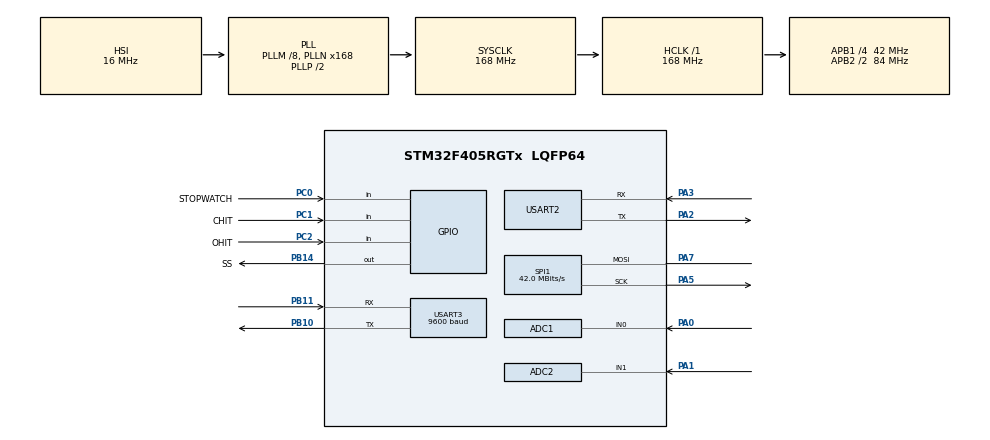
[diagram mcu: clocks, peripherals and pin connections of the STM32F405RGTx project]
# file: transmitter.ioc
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ADC1.Channel-0\#ChannelRegularConversion=ADC_CHANNEL_0
ADC1.NbrOfConversionFlag=1
ADC1.Rank-0\#ChannelRegularConversion=1
ADC1.SamplingTime-0\#ChannelRegularConversion=ADC_SAMPLETIME_28CYCLES
ADC1.master=1
ADC2.Channel-0\#ChannelRegularConversion=ADC_CHANNEL_1
ADC2.NbrOfConversionFlag=1
ADC2.Rank-0\#ChannelRegularConversion=1
ADC2.SamplingTime-0\#ChannelRegularConversion=ADC_SAMPLETIME_28CYCLES
Mcu.Family=STM32F4
Mcu.Name=STM32F405RGTx
Mcu.Package=LQFP64
NVIC.PriorityGroup=NVIC_PRIORITYGROUP_4
NVIC.TIM2_IRQn=true\:0\:0\:false\:false\:true\:true\:true\:true
PA0-WKUP.Signal=ADCx_IN0
PA1.Signal=ADCx_IN1
PA2.Mode=Asynchronous
PA2.Signal=USART2_TX
PA3.Mode=Asynchronous
PA3.Signal=USART2_RX
PA5.Mode=Simplex_Bidirectional_Master
PA5.Signal=SPI1_SCK
PA7.Mode=Simplex_Bidirectional_Master
PA7.Signal=SPI1_MOSI
PB10.Mode=Asynchronous
PB10.Signal=USART3_TX
PB11.Mode=Asynchronous
PB11.Signal=USART3_RX
PB14.GPIO_Label=SS
PB14.Signal=GPIO_Output
PC0.GPIO_Label=STOPWATCH
PC0.Signal=GPIO_Input
PC1.GPIO_Label=CHIT
PC1.Signal=GPIO_Input
PC2.GPIO_Label=OHIT
PC2.Signal=GPIO_Input
ProjectManager.HeapSize=0x200
ProjectManager.StackSize=0x400
ProjectManager.TargetToolchain=STM32CubeIDE
RCC.48MHZClocksFreq_Value=84000000
RCC.AHBFreq_Value=168000000
RCC.APB1CLKDivider=RCC_HCLK_DIV4
RCC.APB1Freq_Value=42000000
RCC.APB1TimFreq_Value=84000000
RCC.APB2CLKDivider=RCC_HCLK_DIV2
RCC.APB2Freq_Value=84000000
RCC.APB2TimFreq_Value=168000000
RCC.CortexFreq_Value=168000000
RCC.HCLKFreq_Value=168000000
RCC.HSE_VALUE=25000000
RCC.HSI_VALUE=16000000
RCC.LSE_VALUE=32768
RCC.PLLM=8
RCC.PLLN=168
RCC.SYSCLKFreq_VALUE=168000000
RCC.SYSCLKSource=RCC_SYSCLKSOURCE_PLLCLK
RCC.VCOOutputFreq_Value=336000000
SH.ADCx_IN0.0=ADC1_IN0,IN0
SH.ADCx_IN1.0=ADC2_IN1,IN1
SPI1.CalculateBaudRate=42.0 MBits/s
SPI1.Direction=SPI_DIRECTION_1LINE
SPI1.Mode=SPI_MODE_MASTER
SPI1.VirtualType=VM_MASTER
TIM2.Period=50000-1
TIM2.Prescaler=16800-1
USART2.VirtualMode=VM_ASYNC
USART3.BaudRate=9600
USART3.VirtualMode=VM_ASYNC
VP_TIM2_VS_ClockSourceINT.Mode=Internal
board=custom

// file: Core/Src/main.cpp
/* USER CODE BEGIN Header */
/**
  ******************************************************************************
  * @file           : main.c
  * @brief          : Main program body
  ******************************************************************************
  * @attention
  *
  * Copyright (c) 2025 STMicroelectronics.
  * All rights reserved.
  *
  * This software is licensed under terms that can be found in the LICENSE file
  * in the root directory of this software component.
  * If no LICENSE file comes with this software, it is provided AS-IS.
  *
  ******************************************************************************
  */
/* USER CODE END Header */
//#include "main.h"
extern "C" {
#include "main.h"  // good enough
}
#include "lora.hpp"

ADC_HandleTypeDef hadc1;
ADC_HandleTypeDef hadc2;

SPI_HandleTypeDef hspi1;

TIM_HandleTypeDef htim2;

UART_HandleTypeDef huart2;
UART_HandleTypeDef huart3;

void SystemClock_Config(void);
static void MX_GPIO_Init(void);
static void MX_ADC1_Init(void);
static void MX_ADC2_Init(void);
static void MX_TIM2_Init(void);
static void MX_USART2_UART_Init(void);
static void MX_USART3_UART_Init(void);
static void MX_SPI1_Init(void);

/* USER CODE BEGIN 0 */
void HAL_TIM_PeriodElapsedCallback(TIM_HandleTypeDef *htim)
  {
      if (htim->Instance == TIM2)
      {
    	  //ADC data to soc
    	  //lcd_update

          //HAL_GPIO_TogglePin(GPIOA, GPIO_PIN_5);  // Toggle the LED
      }
  }
/* USER CODE END 0 */

int main(void)
{

  /* MCU Configuration--------------------------------------------------------*/

  /* Reset of all peripherals, Initializes the Flash interface and the Systick. */
  HAL_Init();

  /* Configure the system clock */
  SystemClock_Config();

  /* Initialize all configured peripherals */
  MX_GPIO_Init();
  MX_ADC1_Init();
  MX_ADC2_Init();
  MX_TIM2_Init();
  MX_USART2_UART_Init();
  MX_USART3_UART_Init();
  MX_SPI1_Init();
  HAL_TIM_Base_Start_IT(&htim2);  // Start TIM2 in interrupt mode
  lora_init();

  /* Infinite loop */
  while (1)
  {
	  if(HAL_GPIO_ReadPin(GPIOC,CHIT_Pin)||HAL_GPIO_ReadPin(GPIOC, OHIT_Pin)||HAL_GPIO_ReadPin(GPIOC, STOPWATCH_Pin)){
		  if(HAL_GPIO_ReadPin(GPIOC,CHIT_Pin))
			  lora_send_char('2');
		  else if(HAL_GPIO_ReadPin(GPIOC, OHIT_Pin))
			  lora_send_char('1');
		  else if(HAL_GPIO_ReadPin(GPIOC, STOPWATCH_Pin)){
			  //do something
		  }
	  }
  }
}

void SystemClock_Config(void)
{
  RCC_OscInitTypeDef RCC_OscInitStruct = {0};
  RCC_ClkInitTypeDef RCC_ClkInitStruct = {0};

  /** Configure the main internal regulator output voltage
  */
  __HAL_RCC_PWR_CLK_ENABLE();
  __HAL_PWR_VOLTAGESCALING_CONFIG(PWR_REGULATOR_VOLTAGE_SCALE1);

  /** Initializes the RCC Oscillators according to the specified parameters
  * in the RCC_OscInitTypeDef structure.
  */
  RCC_OscInitStruct.OscillatorType = RCC_OSCILLATORTYPE_HSI;
  RCC_OscInitStruct.HSIState = RCC_HSI_ON;
  RCC_OscInitStruct.HSICalibrationValue = RCC_HSICALIBRATION_DEFAULT;
  RCC_OscInitStruct.PLL.PLLState = RCC_PLL_ON;
  RCC_OscInitStruct.PLL.PLLSource = RCC_PLLSOURCE_HSI;
  RCC_OscInitStruct.PLL.PLLM = 8;
  RCC_OscInitStruct.PLL.PLLN = 168;
  RCC_OscInitStruct.PLL.PLLP = RCC_PLLP_DIV2;
  RCC_OscInitStruct.PLL.PLLQ = 4;
  if (HAL_RCC_OscConfig(&RCC_OscInitStruct) != HAL_OK)
  {
    Error_Handler();
  }

  /** Initializes the CPU, AHB and APB buses clocks
  */
  RCC_ClkInitStruct.ClockType = RCC_CLOCKTYPE_HCLK|RCC_CLOCKTYPE_SYSCLK
                              |RCC_CLOCKTYPE_PCLK1|RCC_CLOCKTYPE_PCLK2;
  RCC_ClkInitStruct.SYSCLKSource = RCC_SYSCLKSOURCE_PLLCLK;
  RCC_ClkInitStruct.AHBCLKDivider = RCC_SYSCLK_DIV1;
  RCC_ClkInitStruct.APB1CLKDivider = RCC_HCLK_DIV4;
  RCC_ClkInitStruct.APB2CLKDivider = RCC_HCLK_DIV2;

  if (HAL_RCC_ClockConfig(&RCC_ClkInitStruct, FLASH_LATENCY_5) != HAL_OK)
  {
    Error_Handler();
  }
}

static void MX_ADC1_Init(void)
{

  ADC_ChannelConfTypeDef sConfig = {0};

  /** Configure the global features of the ADC (Clock, Resolution, Data Alignment and number of conversion)
  */
  hadc1.Instance = ADC1;
  hadc1.Init.ClockPrescaler = ADC_CLOCK_SYNC_PCLK_DIV4;
  hadc1.Init.Resolution = ADC_RESOLUTION_12B;
  hadc1.Init.ScanConvMode = DISABLE;
  hadc1.Init.ContinuousConvMode = DISABLE;
  hadc1.Init.DiscontinuousConvMode = DISABLE;
  hadc1.Init.ExternalTrigConvEdge = ADC_EXTERNALTRIGCONVEDGE_NONE;
  hadc1.Init.ExternalTrigConv = ADC_SOFTWARE_START;
  hadc1.Init.DataAlign = ADC_DATAALIGN_RIGHT;
  hadc1.Init.NbrOfConversion = 1;
  hadc1.Init.DMAContinuousRequests = DISABLE;
  hadc1.Init.EOCSelection = ADC_EOC_SINGLE_CONV;
  if (HAL_ADC_Init(&hadc1) != HAL_OK)
  {
    Error_Handler();
  }

  /** Configure for the selected ADC regular channel its corresponding rank in the sequencer and its sample time.
  */
  sConfig.Channel = ADC_CHANNEL_0;
  sConfig.Rank = 1;
  sConfig.SamplingTime = ADC_SAMPLETIME_28CYCLES;
  if (HAL_ADC_ConfigChannel(&hadc1, &sConfig) != HAL_OK)
  {
    Error_Handler();
  }

}

static void MX_ADC2_Init(void)
{

  ADC_ChannelConfTypeDef sConfig = {0};

  /** Configure the global features of the ADC (Clock, Resolution, Data Alignment and number of conversion)
  */
  hadc2.Instance = ADC2;
  hadc2.Init.ClockPrescaler = ADC_CLOCK_SYNC_PCLK_DIV4;
  hadc2.Init.Resolution = ADC_RESOLUTION_12B;
  hadc2.Init.ScanConvMode = DISABLE;
  hadc2.Init.ContinuousConvMode = DISABLE;
  hadc2.Init.DiscontinuousConvMode = DISABLE;
  hadc2.Init.ExternalTrigConvEdge = ADC_EXTERNALTRIGCONVEDGE_NONE;
  hadc2.Init.ExternalTrigConv = ADC_SOFTWARE_START;
  hadc2.Init.DataAlign = ADC_DATAALIGN_RIGHT;
  hadc2.Init.NbrOfConversion = 1;
  hadc2.Init.DMAContinuousRequests = DISABLE;
  hadc2.Init.EOCSelection = ADC_EOC_SINGLE_CONV;
  if (HAL_ADC_Init(&hadc2) != HAL_OK)
  {
    Error_Handler();
  }

  /** Configure for the selected ADC regular channel its corresponding rank in the sequencer and its sample time.
  */
  sConfig.Channel = ADC_CHANNEL_1;
  sConfig.Rank = 1;
  sConfig.SamplingTime = ADC_SAMPLETIME_28CYCLES;
  if (HAL_ADC_ConfigChannel(&hadc2, &sConfig) != HAL_OK)
  {
    Error_Handler();
  }

}

static void MX_SPI1_Init(void)
{

  /* SPI1 parameter configuration*/
  hspi1.Instance = SPI1;
  hspi1.Init.Mode = SPI_MODE_MASTER;
  hspi1.Init.Direction = SPI_DIRECTION_1LINE;
  hspi1.Init.DataSize = SPI_DATASIZE_8BIT;
  hspi1.Init.CLKPolarity = SPI_POLARITY_LOW;
  hspi1.Init.CLKPhase = SPI_PHASE_1EDGE;
  hspi1.Init.NSS = SPI_NSS_SOFT;
  hspi1.Init.BaudRatePrescaler = SPI_BAUDRATEPRESCALER_2;
  hspi1.Init.FirstBit = SPI_FIRSTBIT_MSB;
  hspi1.Init.TIMode = SPI_TIMODE_DISABLE;
  hspi1.Init.CRCCalculation = SPI_CRCCALCULATION_DISABLE;
  hspi1.Init.CRCPolynomial = 10;
  if (HAL_SPI_Init(&hspi1) != HAL_OK)
  {
    Error_Handler();
  }

}

static void MX_TIM2_Init(void)
{

  TIM_ClockConfigTypeDef sClockSourceConfig = {0};
  TIM_MasterConfigTypeDef sMasterConfig = {0};

  htim2.Instance = TIM2;
  htim2.Init.Prescaler = 16800-1;
  htim2.Init.CounterMode = TIM_COUNTERMODE_UP;
  htim2.Init.Period = 50000-1;
  htim2.Init.ClockDivision = TIM_CLOCKDIVISION_DIV1;
  htim2.Init.AutoReloadPreload = TIM_AUTORELOAD_PRELOAD_DISABLE;
  if (HAL_TIM_Base_Init(&htim2) != HAL_OK)
  {
    Error_Handler();
  }
  sClockSourceConfig.ClockSource = TIM_CLOCKSOURCE_INTERNAL;
  if (HAL_TIM_ConfigClockSource(&htim2, &sClockSourceConfig) != HAL_OK)
  {
    Error_Handler();
  }
  sMasterConfig.MasterOutputTrigger = TIM_TRGO_RESET;
  sMasterConfig.MasterSlaveMode = TIM_MASTERSLAVEMODE_DISABLE;
  if (HAL_TIMEx_MasterConfigSynchronization(&htim2, &sMasterConfig) != HAL_OK)
  {
    Error_Handler();
  }

}

static void MX_USART2_UART_Init(void)
{

  huart2.Instance = USART2;
  huart2.Init.BaudRate = 115200;
  huart2.Init.WordLength = UART_WORDLENGTH_8B;
  huart2.Init.StopBits = UART_STOPBITS_1;
  huart2.Init.Parity = UART_PARITY_NONE;
  huart2.Init.Mode = UART_MODE_TX_RX;
  huart2.Init.HwFlowCtl = UART_HWCONTROL_NONE;
  huart2.Init.OverSampling = UART_OVERSAMPLING_16;
  if (HAL_UART_Init(&huart2) != HAL_OK)
  {
    Error_Handler();
  }

}

static void MX_USART3_UART_Init(void)
{

  huart3.Instance = USART3;
  huart3.Init.BaudRate = 9600;
  huart3.Init.WordLength = UART_WORDLENGTH_8B;
  huart3.Init.StopBits = UART_STOPBITS_1;
  huart3.Init.Parity = UART_PARITY_NONE;
  huart3.Init.Mode = UART_MODE_TX_RX;
  huart3.Init.HwFlowCtl = UART_HWCONTROL_NONE;
  huart3.Init.OverSampling = UART_OVERSAMPLING_16;
  if (HAL_UART_Init(&huart3) != HAL_OK)
  {
    Error_Handler();
  }

}

static void MX_GPIO_Init(void)
{
  GPIO_InitTypeDef GPIO_InitStruct = {0};

  /* GPIO Ports Clock Enable */
  __HAL_RCC_GPIOC_CLK_ENABLE();
  __HAL_RCC_GPIOA_CLK_ENABLE();
  __HAL_RCC_GPIOB_CLK_ENABLE();

  /*Configure GPIO pin Output Level */
  HAL_GPIO_WritePin(SS_GPIO_Port, SS_Pin, GPIO_PIN_RESET);

  /*Configure GPIO pins : STOPWATCH_Pin CHIT_Pin OHIT_Pin */
  GPIO_InitStruct.Pin = STOPWATCH_Pin|CHIT_Pin|OHIT_Pin;
  GPIO_InitStruct.Mode = GPIO_MODE_INPUT;
  GPIO_InitStruct.Pull = GPIO_NOPULL;
  HAL_GPIO_Init(GPIOC, &GPIO_InitStruct);

  /*Configure GPIO pin : SS_Pin */
  GPIO_InitStruct.Pin = SS_Pin;
  GPIO_InitStruct.Mode = GPIO_MODE_OUTPUT_PP;
  GPIO_InitStruct.Pull = GPIO_NOPULL;
  GPIO_InitStruct.Speed = GPIO_SPEED_FREQ_LOW;
  HAL_GPIO_Init(SS_GPIO_Port, &GPIO_InitStruct);

}

void Error_Handler(void)
{
  __disable_irq();
  while (1)
  {
  }
}
